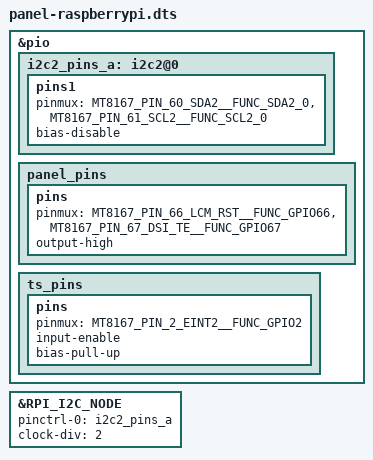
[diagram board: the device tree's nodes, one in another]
/dts-v1/;
/plugin/;

#define RPI_DSI_NODE dsi
#define RPI_I2C_NODE i2c2
#define RPI_MIPI_TX_NODE mipi_tx
#define RPI_PANEL_POWER_SUPPLY mt6392_vgp2_reg
#define RPI_TS_INTERRUPT 2

#include "panel-raspberrypi.dtsi"
#include "mt8167-pinfunc.h"

/ {
	fragment@3 {
		target = <&pio>;
		__overlay__ {
			i2c2_pins_a: i2c2@0 {
				pins1 {
					pinmux = <MT8167_PIN_60_SDA2__FUNC_SDA2_0>,
						 <MT8167_PIN_61_SCL2__FUNC_SCL2_0>;
					bias-disable;
				};
			};

			panel_pins: panel_pins {
				pins {
					pinmux = <MT8167_PIN_66_LCM_RST__FUNC_GPIO66>,
						 <MT8167_PIN_67_DSI_TE__FUNC_GPIO67>;
					output-high;
				};
			};

			ts_pins: ts_pins {
				pins {
					pinmux = <MT8167_PIN_2_EINT2__FUNC_GPIO2>;
					input-enable;
					bias-pull-up;
				};
			};
		};
	};

	fragment@4 {
		target = <&RPI_I2C_NODE>;
		__overlay__ {
			pinctrl-names = "default";
			pinctrl-0 = <&i2c2_pins_a>;
			clock-div = <2>;
		};
	};
};
